# GD32F5HC register map
File version: 1.0
CPU: CM33 r0p4, little endian, MPU, FPU, 4 interrupt priority bits
Registers are 32-bit, read-write, reset 0x0 unless marked. A register's access mark holds for its fields unless they carry their own. Offsets are from the block's base; [hi:lo] are bit positions.

## QSPI — Quad-SPI interface
Base 0x40025800
Same registers: SEC_QSPI 0x50025800
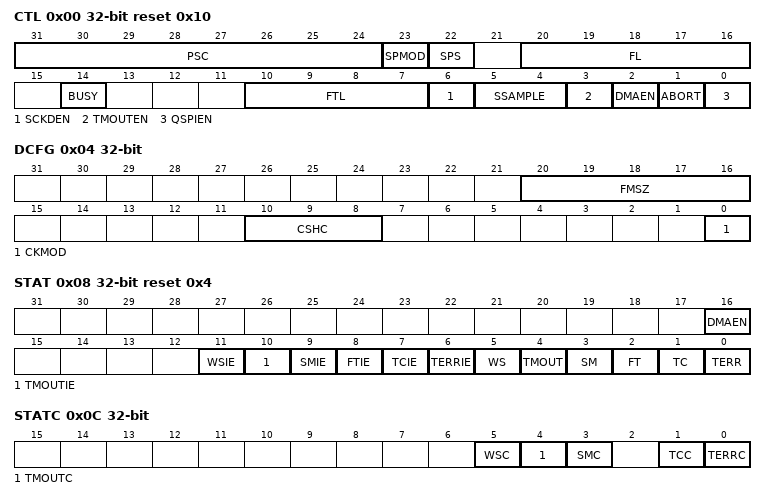
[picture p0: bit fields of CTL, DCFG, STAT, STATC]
0x00 CTL access per field reset 0x10 — control register
  [31:24] PSC rw — The scaler factor for generating SCK
  [23] SPMOD rw — Status Polling match mode
  [22] SPS rw — Status polling mode stop
  [20:16] FL rw — FIFO level
  [14] BUSY ro
  [10:7] FTL rw — FIFO threshold level
  [6] SCKDEN rw — SCK delay enable
  [5:4] SSAMPLE rw — Sample shift
  [3] TMOUTEN rw — Timeout counter enable
  [2] DMAEN rw — DMA enable
  [1] ABORT rw — Abort request
  [0] QSPIEN rw — QSPI enable
0x04 DCFG — Device configuration register
  [20:16] FMSZ — Flash memory size
  [10:8] CSHC — Chip select high cycle
  [0] CKMOD — the SCK level when QSPI is free
0x08 STAT access per field reset 0x4 — status register
  [16] DMAEN rw — DMA enable
  [11] WSIE rw — Wrong start sequence enable
  [10] TMOUTIE rw — Timeout enable
  [9] SMIE rw — Status match enable
  [8] FTIE rw — FIFO threshold enable
  [7] TCIE rw — Transfer complete interrupt enable
  [6] TERRIE rw — Transfer error interrupt enable
  [5] WS ro — Wrong start sequence flag
  [4] TMOUT ro — Timeout flag
  [3] SM ro — Status match flag
  [2] FT ro — FIFO threshold flag
  [1] TC ro — Transfer complete flag
  [0] TERR ro — Transfer error flag
0x0C STATC wo — Status clear register
  [5] WSC — Clear wrong start sequence flag
  [4] TMOUTC — Clear timeout flag
  [3] SMC — Clear status match flag
  [1] TCC — Clear timeout flag
  [0] TERRC — Clear transfer error flag
0x10 DTLEN — Data length register
  [31:0] DTLEN — Data length
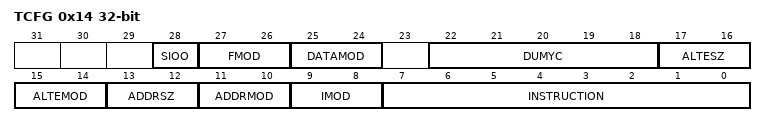
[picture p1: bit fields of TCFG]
0x14 TCFG — Transfer configuration register
  [28] SIOO — Send instruction only once mode
  [27:26] FMOD — Functional mode
  [25:24] DATAMOD — Data mode
  [22:18] DUMYC — Number of dummy cycles
  [17:16] ALTESZ — Alternate bytes size
  [15:14] ALTEMOD — Alternate bytes mode
  [13:12] ADDRSZ — Address size
  [11:10] ADDRMOD — Address mode
  [9:8] IMOD — Instruction mode
  [7:0] INSTRUCTION
0x18 ADDR — Address register
  [31:0] ADDR — Address
0x1C ALTE — Alternate bytes register
  [31:0] ALTE — Alternate Bytes
0x20 DATA
0x24 STATMK — Status mask register
  [31:0] MASK — Status mask
0x28 STATMATCH — Status match register
  [31:0] MATCH — Status match
0x2C INTERVAL
  [31:0] INTERVAL — Interval cycle
0x30 TMOUT — Timeout register
  [15:0] TMOUT — Timeout cycle
0x34 FLUSH — FIFO flush register
  [0] FLUSH — Used to flush all qspi interal fifo

## SPI0 — Serial peripheral interface
Base 0x40013000
Same registers: SEC_SPI0 0x50013000
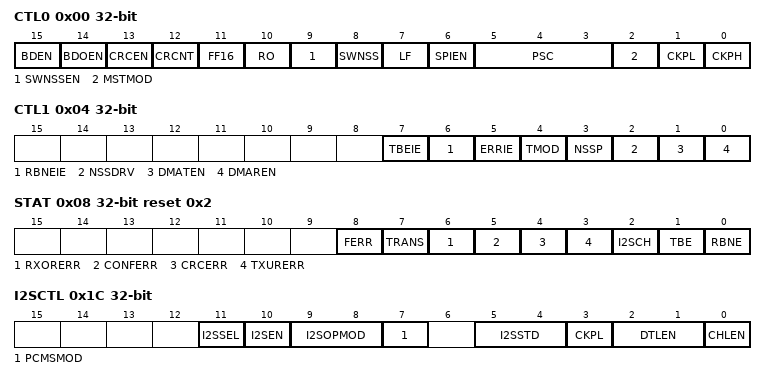
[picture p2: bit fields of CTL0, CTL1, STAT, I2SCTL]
0x00 CTL0 — control register 0
  [15] BDEN — Bidirectional enable
  [14] BDOEN — Bidirectional Transmit output enable
  [13] CRCEN — CRC Calculation Enable
  [12] CRCNT — CRC Next Transfer
  [11] FF16 — Data frame format
  [10] RO — Receive only
  [9] SWNSSEN — NSS Software Mode Selection
  [8] SWNSS — NSS Pin Selection In NSS Software Mode
  [7] LF — LSB First Mode
  [6] SPIEN — SPI enable
  [5:3] PSC — Master Clock Prescaler Selection
  [2] MSTMOD — Master Mode Enable
  [1] CKPL — Clock polarity Selection
  [0] CKPH — Clock Phase Selection
0x04 CTL1 — control register 1
  [7] TBEIE — Tx buffer empty interrupt enable
  [6] RBNEIE — RX buffer not empty interrupt enable
  [5] ERRIE — Error interrupt enable
  [4] TMOD — SPI TI Mode Enable
  [3] NSSP — SPI NSS pulse mode Enable
  [2] NSSDRV — Drive NSS Output
  [1] DMATEN — Transmit Buffer DMA Enable
  [0] DMAREN — Rx buffer DMA enable
0x08 STAT access per field reset 0x2 — status register
  [8] FERR rw — Format Error
  [7] TRANS ro — Transmitting On-going Bit
  [6] RXORERR ro — Reception Overrun Error Bit
  [5] CONFERR ro — SPI Configuration error
  [4] CRCERR rw — SPI CRC Error Bit
  [3] TXURERR ro — Transmission underrun error bit
  [2] I2SCH ro — I2S channel side
  [1] TBE ro — Transmit Buffer Empty
  [0] RBNE ro — Receive Buffer Not Empty
0x0C DATA
  [15:0] SPI_DATA — Data transfer register
0x10 CRCPOLY reset 0x7 — CRC polynomial register
  [15:0] CRCPOLY
0x14 RCRC ro — RX CRC register
  [15:0] RCRC
0x18 TCRC ro — TX CRC register
  [15:0] TCRC — Tx CRC register
0x1C I2SCTL — I2S control register
  [11] I2SSEL — I2S mode selection
  [10] I2SEN — I2S Enable
  [9:8] I2SOPMOD — I2S operation mode
  [7] PCMSMOD — PCM frame synchronization mode
  [5:4] I2SSTD — I2S standard selection
  [3] CKPL — Idle state clock polarity
  [2:1] DTLEN — Data length
  [0] CHLEN — Channel length (number of bits per audio channel)
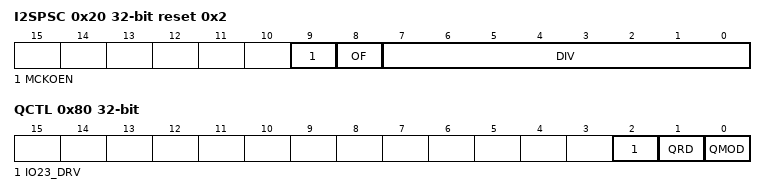
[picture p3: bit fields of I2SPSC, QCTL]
0x20 I2SPSC reset 0x2 — I2S prescaler register
  [9] MCKOEN — I2S_MCK output enable
  [8] OF — Odd factor for the prescaler
  [7:0] DIV — Dividing factor for the prescaler
0x80 QCTL — Quad-SPI mode control register
  [2] IO23_DRV — Drive IO2 and IO3 enable
  [1] QRD — Quad-SPI mode read select
  [0] QMOD — Quad-SPI mode enable

## SPI1 — Serial peripheral interface
Base 0x40003800
Same registers: I2S1_add 0x40003400, SEC_I2S1_add 0x50003400, SEC_SPI1 0x50003800
Registers as SPI0, without QCTL.
